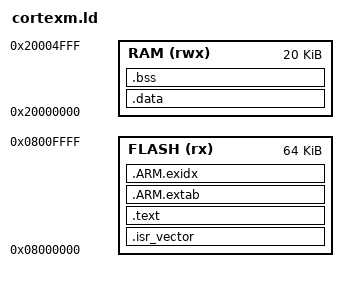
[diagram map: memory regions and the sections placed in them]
/* Minimal Cortex-M linker script for microbench programs */
ENTRY(Reset_Handler)

MEMORY
{
  FLASH (rx)  : ORIGIN = 0x08000000, LENGTH = 64K
  RAM   (rwx) : ORIGIN = 0x20000000, LENGTH = 20K
}

_estack = ORIGIN(RAM) + LENGTH(RAM);

SECTIONS
{
  .isr_vector ORIGIN(FLASH) :
  {
    KEEP(*(.isr_vector))
  } > FLASH

  .text :
  {
    *(.text*)
    *(.rodata*)
  } > FLASH

  .ARM.extab : { *(.ARM.extab*) } > FLASH
  .ARM.exidx  : { *(.ARM.exidx*) } > FLASH

  _sidata = .;

  .data : AT(_sidata)
  {
    _sdata = .;
    *(.data*)
    _edata = .;
  } > RAM

  .bss (NOLOAD) :
  {
    _sbss = .;
    *(.bss*)
    *(COMMON)
    _ebss = .;
  } > RAM

  PROVIDE(__stack_top__ = _estack);
  PROVIDE(end = _ebss);        /* needed by _sbrk for heap (sprintf, etc.) */
  PROVIDE(_end = _ebss);
}
